# Generic_ARMv8MBaseline register map
Vendor: ARM Ltd.; Series: ARMv8-M Baseline architecture (Cortex-M23); File version: 1.0
CPU: CM23 r0p0, little endian, no MPU, no FPU, 2 interrupt priority bits
Registers are 32-bit, read-write, reset 0x0 unless marked. A register's access mark holds for its fields unless they carry their own. Offsets are from the block's base; [hi:lo] are bit positions; {n}, {i} and the like mark numbered series.

## MPU — Memory Protection Unit -- OPTIONAL on ARMv8-M Baseline (__MPU_PRESENT). Region format changed from ARMv7-M's RBAR/RASR (base + size-encoded) to RBAR/RLAR (base + limit), and gained MAIR0/MAIR1 memory-attribute indirection registers (verified against CMSIS_6 core_cm23.h/core_cm33.h). No alias registers on Baseline, matching ARMv6-M's MPU shape.
Base 0xE000ED90
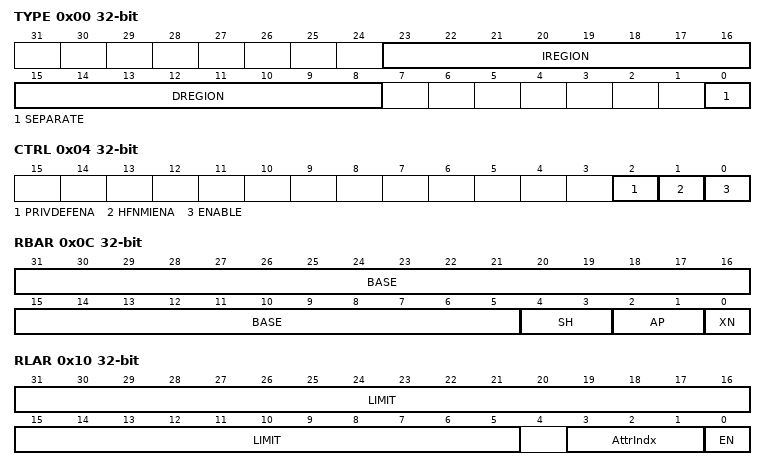
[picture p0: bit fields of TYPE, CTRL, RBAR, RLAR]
0x00 TYPE ro — MPU Type Register
  [23:16] IREGION, [15:8] DREGION, [0] SEPARATE
0x04 CTRL — MPU Control Register
  [2] PRIVDEFENA, [1] HFNMIENA, [0] ENABLE
0x08 RNR — MPU Region Number Register
  [7:0] REGION
0x0C RBAR — MPU Region Base Address Register
  [31:5] BASE — Base address, 32-byte aligned
  [4:3] SH — Shareability
  [2:1] AP — Access permissions
  [0] XN — Execute-never
0x10 RLAR — MPU Region Limit Address Register
  [31:5] LIMIT — Limit address, 32-byte aligned
  [3:1] AttrIndx — MAIR index
  [0] EN — Region enable
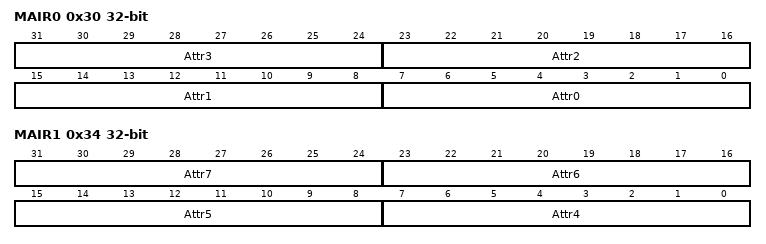
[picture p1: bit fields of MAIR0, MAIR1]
0x30 MAIR0 — MPU Memory Attribute Indirection Register 0
  [8n+7:8n] Attr{n} (n=0..3)
0x34 MAIR1 — MPU Memory Attribute Indirection Register 1
  [8n-25:8n-32] Attr{n} (n=4..7)

## SAU — Security Attribution Unit -- present only when the Security Extension (TrustZone) is implemented; absent entirely on a Non-secure-only/single-state part. RNR/RBAR/RLAR are further optional within that: only present when __SAUREGION_PRESENT=1, i.e. the implementation has at least one programmable SAU region (a part can implement the Security Extension with the whole memory map fixed Secure/Non-secure by IDAU alone and no SAU regions at all). Verified against CMSIS_6 core_cm23.h/core_cm33.h (identical on both profiles). SFSR/SFAR are modeled once, under SCB, since SAU_Type and SCB_Type both expose the same physical registers at the same address on Mainline -- CMSIS_6 now says so explicitly (SAU_Type's own SFSR/SFAR are commented "deprecated: use SCB->SFSR"/"SCB->SFAR"); Baseline has neither (no SecureFault handler exists there).
Base 0xE000EDD0
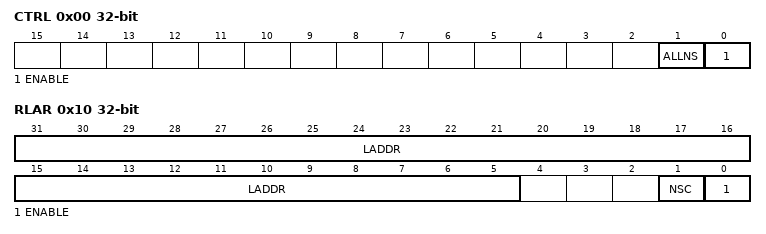
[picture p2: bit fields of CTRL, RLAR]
0x00 CTRL — SAU Control Register
  [1] ALLNS — All Non-secure -- forces the whole memory map Non-secure when SAU is disabled
  [0] ENABLE
0x04 TYPE ro — SAU Type Register
  [7:0] SREGION — Number of implemented SAU regions
0x08 RNR — SAU Region Number Register -- only present if __SAUREGION_PRESENT
  [7:0] REGION
0x0C RBAR — SAU Region Base Address Register -- only present if __SAUREGION_PRESENT
  [31:5] BADDR — Base address, 32-byte aligned
0x10 RLAR — SAU Region Limit Address Register -- only present if __SAUREGION_PRESENT
  [31:5] LADDR — Limit address, 32-byte aligned
  [1] NSC — Non-secure Callable
  [0] ENABLE

## SysTick — SysTick Timer. Identical register set on every Cortex-M core (ARMv6-M through current ARMv8-M).
Base 0xE000E010
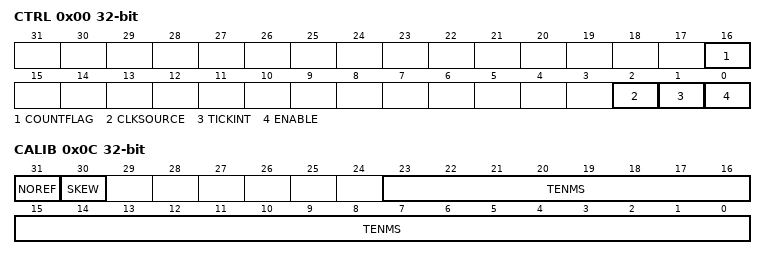
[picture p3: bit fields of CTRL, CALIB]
0x00 CTRL — SysTick Control and Status Register
  [16] COUNTFLAG ro, [2] CLKSOURCE, [1] TICKINT, [0] ENABLE
0x04 LOAD — SysTick Reload Value Register
  [23:0] RELOAD
0x08 VAL — SysTick Current Value Register. Any write clears it to 0 and clears COUNTFLAG.
  [23:0] CURRENT
0x0C CALIB ro — SysTick Calibration Value Register
  [31] NOREF, [30] SKEW, [23:0] TENMS

## DCB — Debug Control Block -- CMSIS's ARMv8-M name for what core_cm0.h/core_cm3.h call CoreDebug (same base address, 0xE000EDF0). Adds DAUTHCTRL (Debug Authentication Control) and DSCSR (Debug Security Control and Status) versus ARMv6-M/ARMv7-M's CoreDebug -- both Security-Extension-related, present regardless of profile. Verified against CMSIS_6 core_cm23.h/core_cm33.h. Baseline's DHCSR has no C_SNAPSTALL bit, and DEMCR only defines TRCENA/VC_CORERESET/VC_HARDERR -- no other VC_*, no MON_*, no MONPRKEY/UMON_EN/SDME/VC_SFERR -- matching Baseline's minimal exception model.
Base 0xE000EDF0
0x00 DHCSR — Debug Halting Control and Status Register
  [26] S_RESTART_ST ro — New in ARMv8-M
  [25] S_RESET_ST ro
  [24] S_RETIRE_ST ro
  [20] S_SDE ro — Secure Debug Enabled -- Security Extension only
  [19] S_LOCKUP ro
  [18] S_SLEEP ro
  [17] S_HALT ro
  [16] S_REGRDY ro
  [31:16] DBGKEY wo — Write 0xA05F to enable write access to bits [15:0]; reads as 0
  [3] C_MASKINTS
  [2] C_STEP
  [1] C_HALT
  [0] C_DEBUGEN
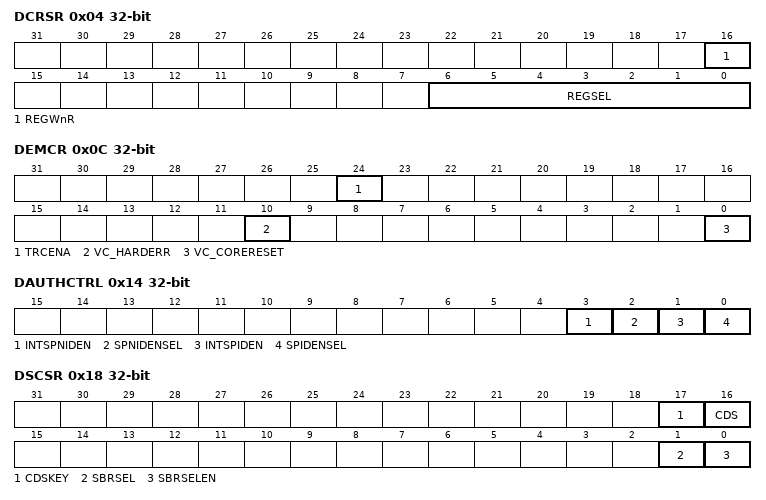
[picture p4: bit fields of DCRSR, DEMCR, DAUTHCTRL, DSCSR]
0x04 DCRSR wo — Debug Core Register Selector Register
  [16] REGWnR, [6:0] REGSEL
0x08 DCRDR — Debug Core Register Data Register
  [31:0] DBGTMP
0x0C DEMCR — Debug Exception and Monitor Control Register
  [24] TRCENA — Trace enable (DWT/ITM/ETM/TPIU) -- only meaningful where those blocks exist
  [10] VC_HARDERR — Debug trap on HardFault exception
  [0] VC_CORERESET — Reset Vector Catch
0x14 DAUTHCTRL — Debug Authentication Control Register -- Security Extension only
  [3] INTSPNIDEN — Internal Secure non-invasive debug enable
  [2] SPNIDENSEL — Secure non-invasive debug enable select
  [1] INTSPIDEN — Internal Secure invasive debug enable
  [0] SPIDENSEL — Secure invasive debug enable select
0x18 DSCSR — Debug Security Control and Status Register -- Security Extension only
  [17] CDSKEY wo — CDS write-enable key
  [16] CDS ro — Current Domain Secure
  [1] SBRSEL — Secure banked register select
  [0] SBRSELEN — Secure banked register select enable
